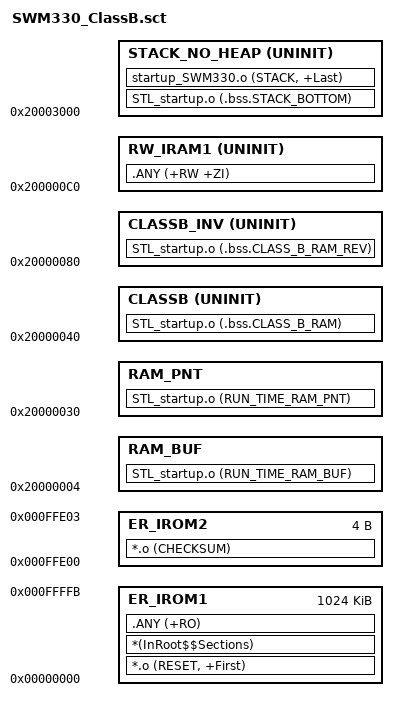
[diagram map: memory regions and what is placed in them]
; *************************************************************
; *** Scatter-Loading Description File generated by uVision ***
; *************************************************************

LR_IROM1 0x00000000 0x000FFFFC {    ; load region size_region 载荷区尺寸区
    ER_IROM1 0x00000000 0x000FFFFC  {  ; load address = execution address 加载地址=执行地址
      *.o (RESET, +First)
      *(InRoot$$Sections)
      .ANY (+RO)
    }
    RAM_BUF 0x20000004 {			; Run-time transparent RAM test buffer 运行时透明RAM测试缓冲区
      STL_startup.o (RUN_TIME_RAM_BUF)
    }

    RAM_PNT 0x20000030 {			; Run-time transparent RAM test pointer 运行时透明RAM测试指针
      STL_startup.o (RUN_TIME_RAM_PNT)
    }

	; Only ZI data in execution region with the UNINIT attribute remains un-initialized
	; AC6 only creates ZI sections if the section name starts with ".bss"
	; Thus, for AC6, to ensure a variable is not initialized, we need to place it in a 
	; section name starts with ".bss" and place the section in a region with UNINIT attribute
    CLASSB 0x20000040 UNINIT {		        ; Class B variables CLASSB变量
    STL_startup.o (.bss.CLASS_B_RAM)
    }

    CLASSB_INV 0x20000080 UNINIT {              ; Class B inverted variables CLASSB倒变量
    STL_startup.o (.bss.CLASS_B_RAM_REV)
    }

    RW_IRAM1 0x200000C0 UNINIT {     ; RW data (Class A variables) RW数据(A类变量)
      .ANY (+RW +ZI)
    }
    
    STACK_NO_HEAP 0x20003000 UNINIT { ; Stack and magic pattern for stack overflow detection 堆栈和魔术模式堆栈溢出检测
    STL_startup.o (.bss.STACK_BOTTOM)
    startup_SWM330.o (STACK, +Last)
    }
	
  }
  ; CHECKSUM on the first address of the last block, where the block size is the runtime ROM crc size
LR_IROM2 0x000FFE00  0x4 {    ; load region size_region 载荷区尺寸区
	ER_IROM2 0x000FFE00 0x4 {
	  *.o (CHECKSUM)
    }
  }
